# ioADuCM302x register map
Registers are 16-bit, access not given, no defined reset value unless marked. A register's access mark holds for its fields unless they carry their own. Addresses are absolute; registers are grouped by the start of their names; [hi:lo] are bit positions.

## SPI0
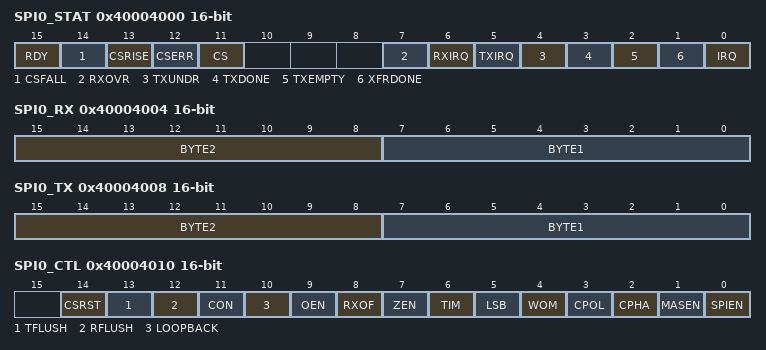
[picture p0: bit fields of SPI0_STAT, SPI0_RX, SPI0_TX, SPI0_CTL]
0x40004000 SPI0_STAT
  [15] RDY, [14] CSFALL, [13] CSRISE, [12] CSERR, [11] CS, [7] RXOVR, [6] RXIRQ, [5] TXIRQ, [4] TXUNDR, [3] TXDONE, [2] TXEMPTY, [1] XFRDONE, [0] IRQ
0x40004004 SPI0_RX
  [15:8] BYTE2, [7:0] BYTE1
0x40004008 SPI0_TX
  [15:8] BYTE2, [7:0] BYTE1
0x4000400C SPI0_DIV
  [5:0] VALUE
0x40004010 SPI0_CTL
  [14] CSRST, [13] TFLUSH, [12] RFLUSH, [11] CON, [10] LOOPBACK, [9] OEN, [8] RXOF, [7] ZEN, [6] TIM, [5] LSB, [4] WOM, [3] CPOL, [2] CPHA, [1] MASEN, [0] SPIEN
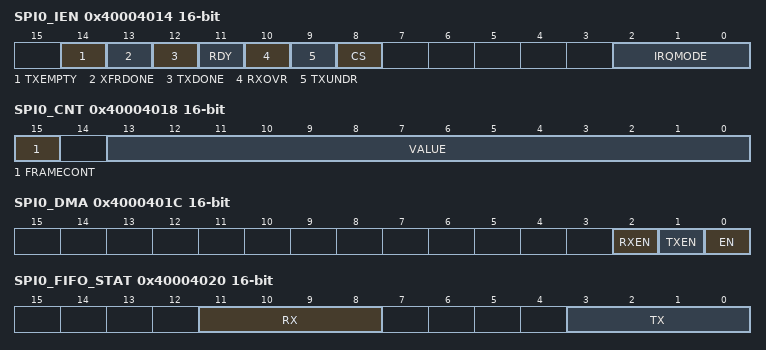
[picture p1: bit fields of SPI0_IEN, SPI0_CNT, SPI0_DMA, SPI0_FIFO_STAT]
0x40004014 SPI0_IEN
  [14] TXEMPTY, [13] XFRDONE, [12] TXDONE, [11] RDY, [10] RXOVR, [9] TXUNDR, [8] CS, [2:0] IRQMODE
0x40004018 SPI0_CNT
  [15] FRAMECONT, [13:0] VALUE
0x4000401C SPI0_DMA
  [2] RXEN, [1] TXEN, [0] EN
0x40004020 SPI0_FIFO_STAT
  [11:8] RX, [3:0] TX
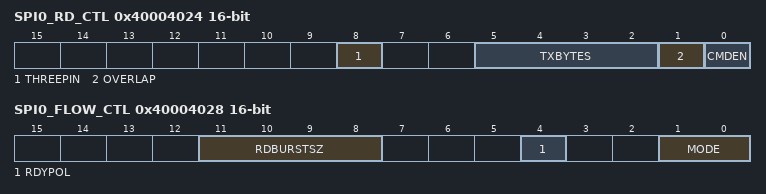
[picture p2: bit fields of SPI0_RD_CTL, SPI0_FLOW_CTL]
0x40004024 SPI0_RD_CTL
  [8] THREEPIN, [5:2] TXBYTES, [1] OVERLAP, [0] CMDEN
0x40004028 SPI0_FLOW_CTL
  [11:8] RDBURSTSZ, [4] RDYPOL, [1:0] MODE
0x4000402C SPI0_WAIT_TMR
0x40004030 SPI0_CS_CTL
  [3:0] SEL
0x40004034 SPI0_CS_OVERRIDE
  [1:0] CTL

## SPI1
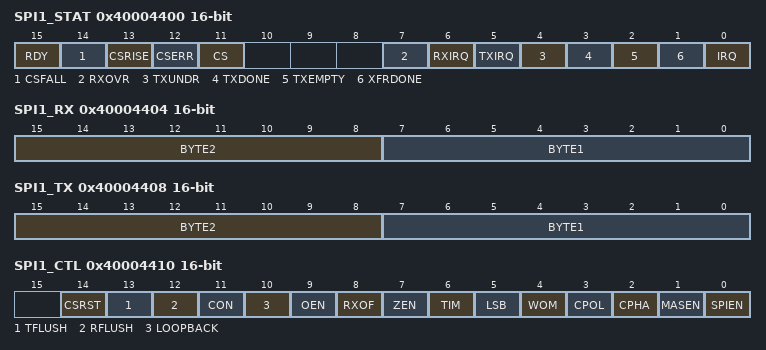
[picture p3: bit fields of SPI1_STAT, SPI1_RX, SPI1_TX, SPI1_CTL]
0x40004400 SPI1_STAT
  [15] RDY, [14] CSFALL, [13] CSRISE, [12] CSERR, [11] CS, [7] RXOVR, [6] RXIRQ, [5] TXIRQ, [4] TXUNDR, [3] TXDONE, [2] TXEMPTY, [1] XFRDONE, [0] IRQ
0x40004404 SPI1_RX
  [15:8] BYTE2, [7:0] BYTE1
0x40004408 SPI1_TX
  [15:8] BYTE2, [7:0] BYTE1
0x4000440C SPI1_DIV
  [5:0] VALUE
0x40004410 SPI1_CTL
  [14] CSRST, [13] TFLUSH, [12] RFLUSH, [11] CON, [10] LOOPBACK, [9] OEN, [8] RXOF, [7] ZEN, [6] TIM, [5] LSB, [4] WOM, [3] CPOL, [2] CPHA, [1] MASEN, [0] SPIEN
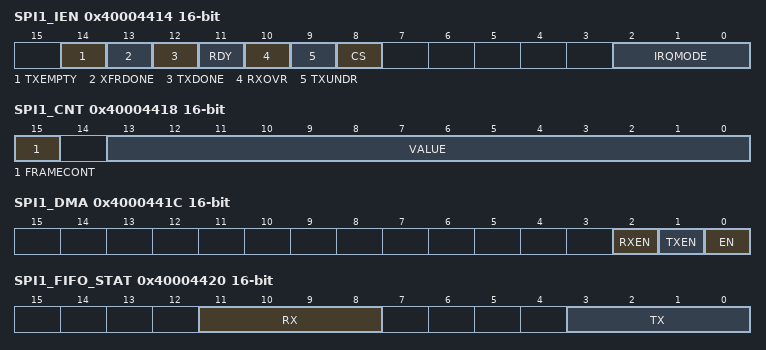
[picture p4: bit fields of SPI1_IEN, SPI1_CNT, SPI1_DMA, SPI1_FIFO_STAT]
0x40004414 SPI1_IEN
  [14] TXEMPTY, [13] XFRDONE, [12] TXDONE, [11] RDY, [10] RXOVR, [9] TXUNDR, [8] CS, [2:0] IRQMODE
0x40004418 SPI1_CNT
  [15] FRAMECONT, [13:0] VALUE
0x4000441C SPI1_DMA
  [2] RXEN, [1] TXEN, [0] EN
0x40004420 SPI1_FIFO_STAT
  [11:8] RX, [3:0] TX
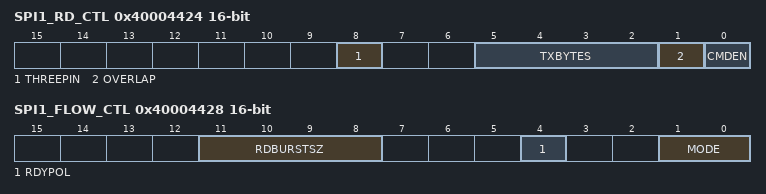
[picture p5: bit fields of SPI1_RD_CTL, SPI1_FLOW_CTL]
0x40004424 SPI1_RD_CTL
  [8] THREEPIN, [5:2] TXBYTES, [1] OVERLAP, [0] CMDEN
0x40004428 SPI1_FLOW_CTL
  [11:8] RDBURSTSZ, [4] RDYPOL, [1:0] MODE
0x4000442C SPI1_WAIT_TMR
0x40004430 SPI1_CS_CTL
  [3:0] SEL
0x40004434 SPI1_CS_OVERRIDE
  [1:0] CTL

## SPI2
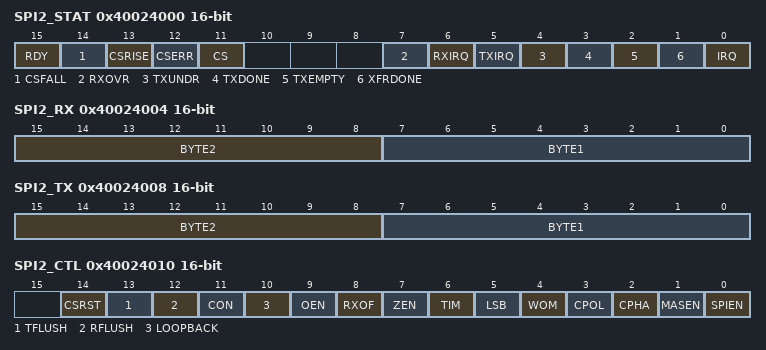
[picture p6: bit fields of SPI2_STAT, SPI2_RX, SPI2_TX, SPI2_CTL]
0x40024000 SPI2_STAT
  [15] RDY, [14] CSFALL, [13] CSRISE, [12] CSERR, [11] CS, [7] RXOVR, [6] RXIRQ, [5] TXIRQ, [4] TXUNDR, [3] TXDONE, [2] TXEMPTY, [1] XFRDONE, [0] IRQ
0x40024004 SPI2_RX
  [15:8] BYTE2, [7:0] BYTE1
0x40024008 SPI2_TX
  [15:8] BYTE2, [7:0] BYTE1
0x4002400C SPI2_DIV
  [5:0] VALUE
0x40024010 SPI2_CTL
  [14] CSRST, [13] TFLUSH, [12] RFLUSH, [11] CON, [10] LOOPBACK, [9] OEN, [8] RXOF, [7] ZEN, [6] TIM, [5] LSB, [4] WOM, [3] CPOL, [2] CPHA, [1] MASEN, [0] SPIEN
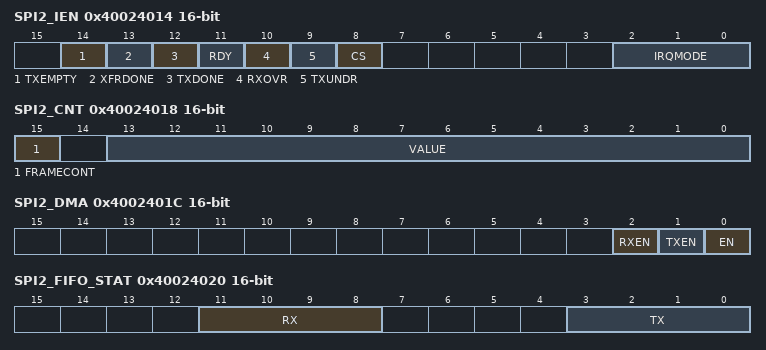
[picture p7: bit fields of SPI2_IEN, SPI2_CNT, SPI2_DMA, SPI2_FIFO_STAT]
0x40024014 SPI2_IEN
  [14] TXEMPTY, [13] XFRDONE, [12] TXDONE, [11] RDY, [10] RXOVR, [9] TXUNDR, [8] CS, [2:0] IRQMODE
0x40024018 SPI2_CNT
  [15] FRAMECONT, [13:0] VALUE
0x4002401C SPI2_DMA
  [2] RXEN, [1] TXEN, [0] EN
0x40024020 SPI2_FIFO_STAT
  [11:8] RX, [3:0] TX
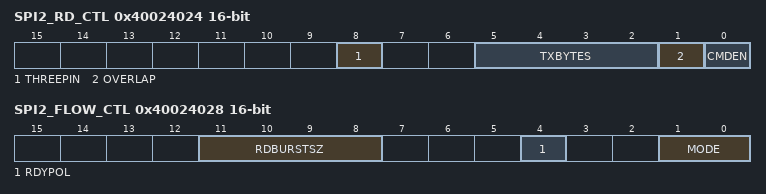
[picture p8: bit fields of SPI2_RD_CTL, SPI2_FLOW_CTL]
0x40024024 SPI2_RD_CTL
  [8] THREEPIN, [5:2] TXBYTES, [1] OVERLAP, [0] CMDEN
0x40024028 SPI2_FLOW_CTL
  [11:8] RDBURSTSZ, [4] RDYPOL, [1:0] MODE
0x4002402C SPI2_WAIT_TMR
0x40024030 SPI2_CS_CTL
  [3:0] SEL
0x40024034 SPI2_CS_OVERRIDE
  [1:0] CTL

## UART0
0x40005000 UART0_RX
  [7:0] RBR
0x40005000 UART0_TX
  [7:0] THR
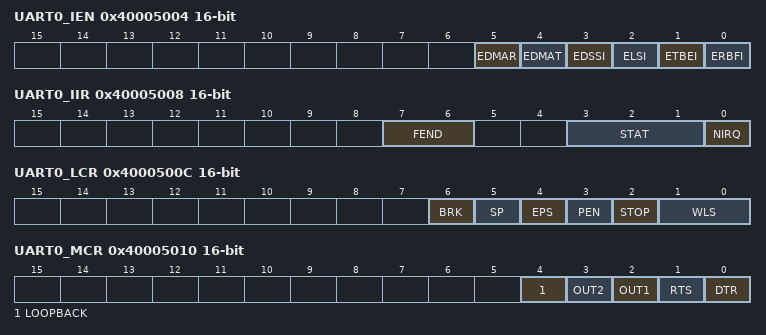
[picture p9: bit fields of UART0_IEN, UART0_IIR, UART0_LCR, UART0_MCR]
0x40005004 UART0_IEN
  [5] EDMAR, [4] EDMAT, [3] EDSSI, [2] ELSI, [1] ETBEI, [0] ERBFI
0x40005008 UART0_IIR
  [7:6] FEND, [3:1] STAT, [0] NIRQ
0x4000500C UART0_LCR
  [6] BRK, [5] SP, [4] EPS, [3] PEN, [2] STOP, [1:0] WLS
0x40005010 UART0_MCR
  [4] LOOPBACK, [3] OUT2, [2] OUT1, [1] RTS, [0] DTR
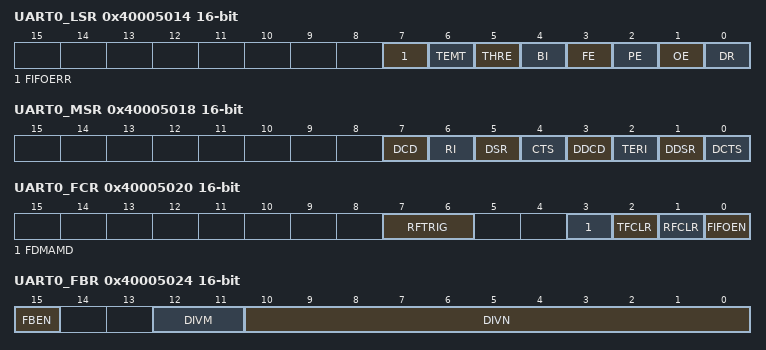
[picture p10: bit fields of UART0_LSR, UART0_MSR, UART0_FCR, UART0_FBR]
0x40005014 UART0_LSR
  [7] FIFOERR, [6] TEMT, [5] THRE, [4] BI, [3] FE, [2] PE, [1] OE, [0] DR
0x40005018 UART0_MSR
  [7] DCD, [6] RI, [5] DSR, [4] CTS, [3] DDCD, [2] TERI, [1] DDSR, [0] DCTS
0x4000501C UART0_SCR
  [7:0] SCR
0x40005020 UART0_FCR
  [7:6] RFTRIG, [3] FDMAMD, [2] TFCLR, [1] RFCLR, [0] FIFOEN
0x40005024 UART0_FBR
  [15] FBEN, [12:11] DIVM, [10:0] DIVN
0x40005028 UART0_DIV
0x4000502C UART0_LCR2
  [1:0] OSR
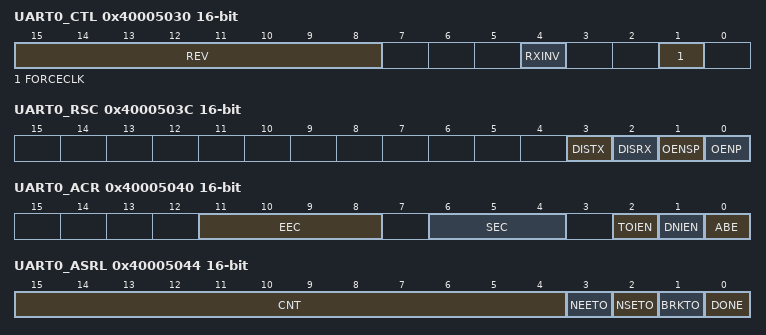
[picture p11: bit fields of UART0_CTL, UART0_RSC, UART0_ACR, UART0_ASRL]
0x40005030 UART0_CTL
  [15:8] REV, [4] RXINV, [1] FORCECLK
0x40005034 UART0_RFC
  [4:0] RFC
0x40005038 UART0_TFC
  [4:0] TFC
0x4000503C UART0_RSC
  [3] DISTX, [2] DISRX, [1] OENSP, [0] OENP
0x40005040 UART0_ACR
  [11:8] EEC, [6:4] SEC, [2] TOIEN, [1] DNIEN, [0] ABE
0x40005044 UART0_ASRL
  [15:4] CNT, [3] NEETO, [2] NSETO, [1] BRKTO, [0] DONE
0x40005048 UART0_ASRH
  [7:0] CNT
